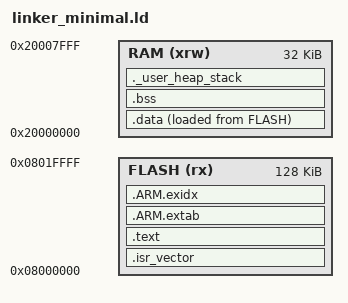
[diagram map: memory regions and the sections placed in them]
ENTRY(Reset_Handler)

MEMORY
{
  FLASH (rx)  : ORIGIN = 0x08000000, LENGTH = 128K
  RAM   (xrw) : ORIGIN = 0x20000000, LENGTH = 32K
}

_estack = ORIGIN(RAM) + LENGTH(RAM);

SECTIONS
{
  .isr_vector :
  {
    . = ALIGN(4);
    KEEP(*(.isr_vector))
    . = ALIGN(4);
  } > FLASH

  .text :
  {
    . = ALIGN(4);
    *(.text)
    *(.text*)
    *(.glue_7)
    *(.glue_7t)
    *(.eh_frame)
    
    KEEP(*(.init))
    KEEP(*(.fini))
    
    . = ALIGN(4);
    *(.rodata)
    *(.rodata*)
    . = ALIGN(4);
    _etext = .;
  } > FLASH

  .ARM.extab : { *(.ARM.extab* .gnu.linkonce.armextab.*) } > FLASH
  .ARM.exidx : { *(.ARM.exidx* .gnu.linkonce.armexidx.*) } > FLASH

  _sidata = LOADADDR(.data);

  .data : 
  {
    . = ALIGN(4);
    _sdata = .;
    *(.data)
    *(.data*)
    . = ALIGN(4);
    _edata = .;
  } > RAM AT> FLASH

  .bss :
  {
    . = ALIGN(4);
    _sbss = .;
    *(.bss)
    *(.bss*)
    *(COMMON)
    . = ALIGN(4);
    _ebss = .;
  } > RAM

  ._user_heap_stack :
  {
    . = ALIGN(8);
    PROVIDE(end = .);
    PROVIDE(_end = .);
    . = . + 0x400;
    . = . + 0x800;
    . = ALIGN(8);
  } > RAM
}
